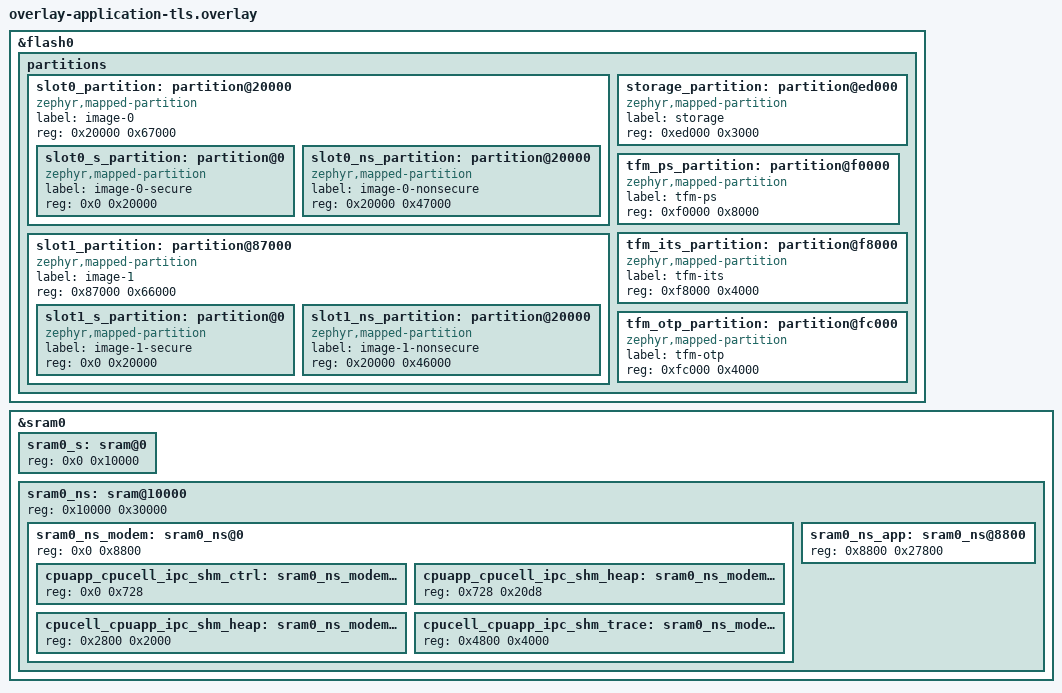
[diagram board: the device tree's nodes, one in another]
/*
 * Copyright (c) 2026 Nordic Semiconductor ASA
 *
 * SPDX-License-Identifier: LicenseRef-Nordic-5-Clause
 *
 * Flash partition layout for nRF9151 DK with application TLS.
 *
 * 0x0000_0000  b0 (NSIB)                    ( 32 kB)
 * 0x0000_8000  s0 (MCUBoot image, slot 0)   ( 48 kB)
 * 0x0001_4000  s1 (MCUBoot image, slot 1)   ( 48 kB)
 * 0x0002_0000  slot0 (primary app)          (412 kB)
 *   0x0002_0000  TF-M secure                   (128 kB)
 *   0x0004_0000  Application (non-secure)      (284 kB)
 * 0x0008_7000  slot1 (secondary app)        (408 kB)
 *   0x0008_7000  TF-M secure                   (128 kB)
 *   0x000a_7000  Application (non-secure)      (280 kB)
 * 0x000e_d000  Non-secure storage           ( 12 kB)
 * 0x000f_0000  TF-M protected storage       ( 32 kB)
 * 0x000f_8000  TF-M internal trusted storage( 16 kB)
 * 0x000f_c000  TF-M OTP counters            ( 16 kB)
 */

/delete-node/ &slot0_partition;
/delete-node/ &slot1_partition;
/delete-node/ &nonsecure_storage;

&flash0 {
	partitions {
		slot0_partition: partition@20000 {
			compatible = "zephyr,mapped-partition";
			label = "image-0";
			reg = <0x20000 0x67000>;
			ranges = <0x0 0x20000 0x67000>;
			#address-cells = <1>;
			#size-cells = <1>;

			slot0_s_partition: partition@0 {
				compatible = "zephyr,mapped-partition";
				label = "image-0-secure";
				reg = <0x0 0x20000>;
			};

			slot0_ns_partition: partition@20000 {
				compatible = "zephyr,mapped-partition";
				label = "image-0-nonsecure";
				reg = <0x20000 0x47000>;
			};
		};

		slot1_partition: partition@87000 {
			compatible = "zephyr,mapped-partition";
			label = "image-1";
			reg = <0x87000 0x66000>;
			ranges = <0x0 0x87000 0x66000>;
			#address-cells = <1>;
			#size-cells = <1>;

			slot1_s_partition: partition@0 {
				compatible = "zephyr,mapped-partition";
				label = "image-1-secure";
				reg = <0x0 0x20000>;
			};

			slot1_ns_partition: partition@20000 {
				compatible = "zephyr,mapped-partition";
				label = "image-1-nonsecure";
				reg = <0x20000 0x46000>;
			};
		};

		storage_partition: partition@ed000 {
			compatible = "zephyr,mapped-partition";
			label = "storage";
			reg = <0xed000 0x3000>;
		};

		tfm_ps_partition: partition@f0000 {
			compatible = "zephyr,mapped-partition";
			label = "tfm-ps";
			reg = <0xf0000 0x8000>;
		};

		tfm_its_partition: partition@f8000 {
			compatible = "zephyr,mapped-partition";
			label = "tfm-its";
			reg = <0xf8000 0x4000>;
		};

		tfm_otp_partition: partition@fc000 {
			compatible = "zephyr,mapped-partition";
			label = "tfm-otp";
			reg = <0xfc000 0x4000>;
		};

	};
};

/*
 * Application SRAM layout for nRF9151 with application TLS:
 *
 * 0x0000_0000  Secure RAM                   (  64 kB)
 * 0x0001_0000  Non-secure RAM area          ( 192 kB)
 *   0x0001_0000  Modem shared area          (  34 kB)
 *     0x0001_0000  control                  (1832 B)
 *     0x0001_0728  app -> cell              (8408 B)
 *     0x0001_2800  cell -> app              (  8 kB)
 *     0x0001_4800  trace                    ( 16 kB)
 *   0x0001_4000  Application RAM            (158 kB)
 */

/delete-node/ &sram0_s;
/delete-node/ &sram0_ns;

&sram0 {

	sram0_s: sram@0 {
		reg = <0x0 0x10000>;
	};

	sram0_ns: sram@10000 {
		reg = <0x10000 0x30000>;
		#address-cells = <1>;
		#size-cells = <1>;
		ranges = <0x0 0x10000 0x30000>;

		/* Must be in first 128 kB of RAM. */
		sram0_ns_modem: sram0_ns@0 {
			/* Modem (shared) memory */
			reg = <0x0 0x8800>;
			#address-cells = <1>;
			#size-cells = <1>;
			ranges = <0x0 0x0 0x8800>;

			cpuapp_cpucell_ipc_shm_ctrl: sram0_ns_modem@0 {
				/* Modem IPC control */
				reg = <0x0 0x728>;
			};

			cpuapp_cpucell_ipc_shm_heap: sram0_ns_modem@728 {
				/* Modem IPC transmit */
				reg = <0x728 0x20d8>;
			};

			cpucell_cpuapp_ipc_shm_heap: sram0_ns_modem@2800 {
				/* Modem IPC receive */
				reg = <0x2800 0x2000>;
			};

			cpucell_cpuapp_ipc_shm_trace: sram0_ns_modem@4800 {
				/* Modem trace memory */
				reg = <0x4800 0x4000>;
			};
		};

		sram0_ns_app: sram0_ns@8800 {
			/* Non-Secure application memory */
			reg = <0x8800 0x27800>;
		};
	};
};
